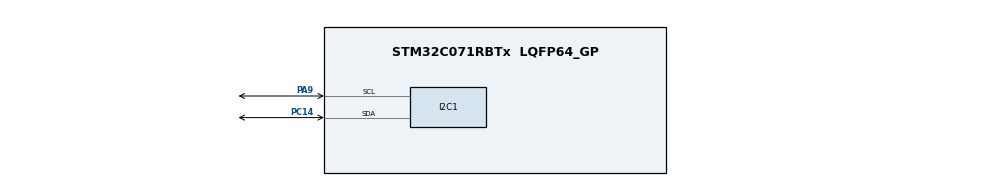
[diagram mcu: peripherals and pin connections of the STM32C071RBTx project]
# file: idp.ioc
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Dma.I2C1_RX.1.Direction=DMA_PERIPH_TO_MEMORY
Dma.I2C1_RX.1.EventEnable=DISABLE
Dma.I2C1_RX.1.Instance=DMA1_Channel2
Dma.I2C1_RX.1.MemDataAlignment=DMA_MDATAALIGN_BYTE
Dma.I2C1_RX.1.MemInc=DMA_MINC_ENABLE
Dma.I2C1_RX.1.Mode=DMA_NORMAL
Dma.I2C1_RX.1.PeriphDataAlignment=DMA_PDATAALIGN_BYTE
Dma.I2C1_RX.1.PeriphInc=DMA_PINC_DISABLE
Dma.I2C1_RX.1.Polarity=HAL_DMAMUX_REQ_GEN_RISING
Dma.I2C1_RX.1.Priority=DMA_PRIORITY_LOW
Dma.I2C1_RX.1.RequestNumber=1
Dma.I2C1_RX.1.SignalID=NONE
Dma.I2C1_RX.1.SyncEnable=DISABLE
Dma.I2C1_RX.1.SyncPolarity=HAL_DMAMUX_SYNC_NO_EVENT
Dma.I2C1_RX.1.SyncRequestNumber=1
Dma.I2C1_RX.1.SyncSignalID=NONE
Dma.I2C1_TX.0.Direction=DMA_MEMORY_TO_PERIPH
Dma.I2C1_TX.0.EventEnable=DISABLE
Dma.I2C1_TX.0.Instance=DMA1_Channel1
Dma.I2C1_TX.0.MemDataAlignment=DMA_MDATAALIGN_BYTE
Dma.I2C1_TX.0.MemInc=DMA_MINC_ENABLE
Dma.I2C1_TX.0.Mode=DMA_NORMAL
Dma.I2C1_TX.0.PeriphDataAlignment=DMA_PDATAALIGN_BYTE
Dma.I2C1_TX.0.PeriphInc=DMA_PINC_DISABLE
Dma.I2C1_TX.0.Polarity=HAL_DMAMUX_REQ_GEN_RISING
Dma.I2C1_TX.0.Priority=DMA_PRIORITY_LOW
Dma.I2C1_TX.0.RequestNumber=1
Dma.I2C1_TX.0.SignalID=NONE
Dma.I2C1_TX.0.SyncEnable=DISABLE
Dma.I2C1_TX.0.SyncPolarity=HAL_DMAMUX_SYNC_NO_EVENT
Dma.I2C1_TX.0.SyncRequestNumber=1
Dma.I2C1_TX.0.SyncSignalID=NONE
Dma.Request0=I2C1_TX
Dma.Request1=I2C1_RX
I2C1.Timing=0x00402D41
Mcu.Family=STM32C0
Mcu.Name=STM32C071RBTx
Mcu.Package=LQFP64_GP
NVIC.DMA1_Channel1_IRQn=true\:0\:0\:false\:false\:true\:false\:true\:true
NVIC.DMA1_Channel2_3_IRQn=true\:0\:0\:false\:false\:true\:false\:true\:true
PA9.Mode=I2C
PA9.Signal=I2C1_SCL
PC14-OSCX_IN(PC14).Mode=I2C
PC14-OSCX_IN(PC14).Signal=I2C1_SDA
ProjectManager.HeapSize=0x200
ProjectManager.StackSize=0x400
ProjectManager.TargetToolchain=STM32CubeIDE
RCC.ADCFreq_Value=12000000
RCC.AHBFreq_Value=12000000
RCC.CortexFreq_Value=12000000
RCC.EXTERNAL_CLOCK_VALUE=12288000
RCC.HCLKFreq_Value=12000000
RCC.HSE_VALUE=8000000
RCC.HSI48_VALUE=48000000
RCC.HSI_VALUE=48000000
RCC.LSE_VALUE=32768
RCC.SYSCLKFreq_VALUE=12000000
board=custom

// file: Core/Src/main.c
/* USER CODE BEGIN Header */
/**
  ******************************************************************************
  * @file           : main.c
  * @brief          : Main program body
  ******************************************************************************
  * @attention
  *
  * Copyright (c) 2026 STMicroelectronics.
  * All rights reserved.
  *
  * This software is licensed under terms that can be found in the LICENSE file
  * in the root directory of this software component.
  * If no LICENSE file comes with this software, it is provided AS-IS.
  *
  ******************************************************************************
  */
/* USER CODE END Header */
#include "main.h"
#include <math.h>

/* USER CODE BEGIN Includes */
#define MPU6050_ADDR (0x68 << 1)

extern I2C_HandleTypeDef hi2c1;

uint8_t buffer[14];

int16_t AccX, AccY, AccZ;
int16_t GyroX, GyroY, GyroZ;

float Ax, Ay, Az;
float Gx, Gy, Gz;

float angleX, angleY;
/* USER CODE END Includes */

I2C_HandleTypeDef hi2c1;
DMA_HandleTypeDef hdma_i2c1_tx;
DMA_HandleTypeDef hdma_i2c1_rx;

void SystemClock_Config(void);
static void MX_GPIO_Init(void);
static void MX_DMA_Init(void);
static void MX_I2C1_Init(void);

/* USER CODE BEGIN 0 */
void MPU6050_Init()
{
    uint8_t data = 0x00;  // wake up

    HAL_I2C_Mem_Write(&hi2c1,
                      MPU6050_ADDR,
                      0x6B,   // PWR_MGMT_1
                      1,
                      &data,
                      1,
                      1000);
}

void MPU6050_Read()
{
    HAL_I2C_Mem_Read(&hi2c1,
                     MPU6050_ADDR,
                     0x3B,   // starting register
                     1,
                     buffer,
                     14,
                     1000);

    // Combine bytes (NO confusion method)
    AccX = (buffer[0] << 8) | buffer[1];
    AccY = (buffer[2] << 8) | buffer[3];
    AccZ = (buffer[4] << 8) | buffer[5];

    GyroX = (buffer[8] << 8) | buffer[9];
    GyroY = (buffer[10] << 8) | buffer[11];
    GyroZ = (buffer[12] << 8) | buffer[13];
}

void MPU6050_Convert()
{
    // Accelerometer (±2g → 16384)
    Ax = AccX / 16384.0;
    Ay = AccY / 16384.0;
    Az = AccZ / 16384.0;

    // Gyroscope (±250°/s → 131)
    Gx = GyroX / 131.0;
    Gy = GyroY / 131.0;
    Gz = GyroZ / 131.0;
}

void MPU6050_Angle()
{
    angleX = atan2(Ay, Az) * 57.3;
    angleY = atan2(Ax, Az) * 57.3;
}
/* USER CODE END 0 */

int main(void)
{

  /* MCU Configuration--------------------------------------------------------*/

  /* Reset of all peripherals, Initializes the Flash interface and the Systick. */
  HAL_Init();

  /* Configure the system clock */
  SystemClock_Config();

  /* Initialize all configured peripherals */
  MX_GPIO_Init();
  MX_DMA_Init();
  MX_I2C1_Init();

  /* Infinite loop */
  while (1)
  {

    /* USER CODE BEGIN 3 */

	  MPU6050_Init();

	      while (1)
	      {
	          MPU6050_Read();
	          MPU6050_Convert();
	          MPU6050_Angle();

	          HAL_Delay(100);
	      }
  }
  /* USER CODE END 3 */
}

void SystemClock_Config(void)
{
  RCC_OscInitTypeDef RCC_OscInitStruct = {0};
  RCC_ClkInitTypeDef RCC_ClkInitStruct = {0};

  __HAL_FLASH_SET_LATENCY(FLASH_LATENCY_0);

  /** Initializes the RCC Oscillators according to the specified parameters
  * in the RCC_OscInitTypeDef structure.
  */
  RCC_OscInitStruct.OscillatorType = RCC_OSCILLATORTYPE_HSI;
  RCC_OscInitStruct.HSIState = RCC_HSI_ON;
  RCC_OscInitStruct.HSIDiv = RCC_HSI_DIV4;
  RCC_OscInitStruct.HSICalibrationValue = RCC_HSICALIBRATION_DEFAULT;
  if (HAL_RCC_OscConfig(&RCC_OscInitStruct) != HAL_OK)
  {
    Error_Handler();
  }

  /** Initializes the CPU, AHB and APB buses clocks
  */
  RCC_ClkInitStruct.ClockType = RCC_CLOCKTYPE_HCLK|RCC_CLOCKTYPE_SYSCLK
                              |RCC_CLOCKTYPE_PCLK1;
  RCC_ClkInitStruct.SYSCLKSource = RCC_SYSCLKSOURCE_HSI;
  RCC_ClkInitStruct.SYSCLKDivider = RCC_SYSCLK_DIV1;
  RCC_ClkInitStruct.AHBCLKDivider = RCC_HCLK_DIV1;
  RCC_ClkInitStruct.APB1CLKDivider = RCC_APB1_DIV1;

  if (HAL_RCC_ClockConfig(&RCC_ClkInitStruct, FLASH_LATENCY_0) != HAL_OK)
  {
    Error_Handler();
  }
}

static void MX_I2C1_Init(void)
{

  hi2c1.Instance = I2C1;
  hi2c1.Init.Timing = 0x00402D41;
  hi2c1.Init.OwnAddress1 = 0;
  hi2c1.Init.AddressingMode = I2C_ADDRESSINGMODE_7BIT;
  hi2c1.Init.DualAddressMode = I2C_DUALADDRESS_DISABLE;
  hi2c1.Init.OwnAddress2 = 0;
  hi2c1.Init.OwnAddress2Masks = I2C_OA2_NOMASK;
  hi2c1.Init.GeneralCallMode = I2C_GENERALCALL_DISABLE;
  hi2c1.Init.NoStretchMode = I2C_NOSTRETCH_DISABLE;
  if (HAL_I2C_Init(&hi2c1) != HAL_OK)
  {
    Error_Handler();
  }

  /** Configure Analogue filter
  */
  if (HAL_I2CEx_ConfigAnalogFilter(&hi2c1, I2C_ANALOGFILTER_ENABLE) != HAL_OK)
  {
    Error_Handler();
  }

  /** Configure Digital filter
  */
  if (HAL_I2CEx_ConfigDigitalFilter(&hi2c1, 0) != HAL_OK)
  {
    Error_Handler();
  }

}

static void MX_DMA_Init(void)
{

  /* DMA controller clock enable */
  __HAL_RCC_DMA1_CLK_ENABLE();

  /* DMA interrupt init */
  /* DMA1_Channel1_IRQn interrupt configuration */
  HAL_NVIC_SetPriority(DMA1_Channel1_IRQn, 0, 0);
  HAL_NVIC_EnableIRQ(DMA1_Channel1_IRQn);
  /* DMA1_Channel2_3_IRQn interrupt configuration */
  HAL_NVIC_SetPriority(DMA1_Channel2_3_IRQn, 0, 0);
  HAL_NVIC_EnableIRQ(DMA1_Channel2_3_IRQn);

}

static void MX_GPIO_Init(void)
{

  /* GPIO Ports Clock Enable */
  __HAL_RCC_GPIOC_CLK_ENABLE();
  __HAL_RCC_GPIOA_CLK_ENABLE();

}

void Error_Handler(void)
{
  __disable_irq();
  while (1)
  {
  }
}
